# CY8C5868AXI_LP035 register map
File version: 0.1
CY8C58LP
Registers are 8-bit, read-write, no defined reset value unless marked. A register's access mark holds for its fields unless they carry their own. Offsets are from the block's base; lines under a group give offsets from that group; [hi:lo] are bit positions; {n}, {i} and the like mark numbered series; 'fields as' and 'values as' point back to an identical list; <NAME> marks a mode.

## Memory map
0x00000000 Rx_Top — UART
0x00000000 Rx_Bottom — UART
0x00000000 Rx_Front — UART
0x00000000 Rx_Left — UART
0x00000000 Rx_Right — UART
0x00000000 Tx — UART
0x00000000 Rx_Back — UART
0x40006460 Rx_Back_Register
0x40006462 Rx_Front_Register
0x40006566 Rx_Left_Register
0x40006567 Rx_Bottom_Register
0x40006568 Rx_Right_Register
0x4000656A Rx_Top_Register

## Rx_Top — UART
Base 0x00000000
0x40006429 RX_Rx_Top_RX_ADDRESS1 — RX Address1 Register
0x40006439 RX_Rx_Top_RX_ADDRESS2 — RX Address2 Register
0x40006449 RX_Rx_Top_RX_DATA — RX Data Register
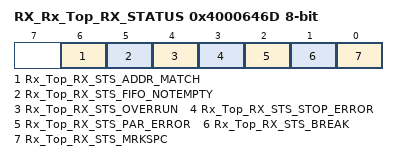
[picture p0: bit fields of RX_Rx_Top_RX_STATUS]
0x4000646D RX_Rx_Top_RX_STATUS — RX status register
  [6] Rx_Top_RX_STS_ADDR_MATCH ro, [5] Rx_Top_RX_STS_FIFO_NOTEMPTY ro, [4] Rx_Top_RX_STS_OVERRUN ro, [3] Rx_Top_RX_STS_STOP_ERROR ro, [2] Rx_Top_RX_STS_PAR_ERROR ro, [1] Rx_Top_RX_STS_BREAK ro, [0] Rx_Top_RX_STS_MRKSPC ro

## Rx_Back_Register
Base 0x40006460
0x00 Rx_Back_Register_STATUS_REG
0x20 Rx_Back_Register_MASK_REG
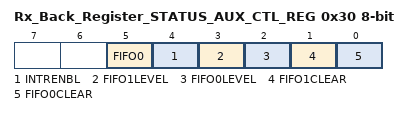
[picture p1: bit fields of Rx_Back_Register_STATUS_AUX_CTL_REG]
0x30 Rx_Back_Register_STATUS_AUX_CTL_REG
  [5] FIFO0 — FIFO0 clear
    1=ENABLED (Enable counter); 0=DISABLED (Disable counter)
  [4] INTRENBL — Enables or disables the Interrupt
    1=ENABLED (Interrupt enabled); 0=DISABLED (Interrupt disabled)
  [3] FIFO1LEVEL — FIFO level
    1=ENABLED (FIFO LVL: input mode: FIFO at least 1/2 empty; output mode: FIFO at least 1/2 full); 0=DISABLED (FIFO LVL: input mode: FIFO not full; output mode: FIFO not empty)
  [2] FIFO0LEVEL — FIFO level
    values as FIFO1LEVEL
  [1] FIFO1CLEAR — FIFO clear
    1=ENABLED (Clear FIFO state); 0=DISABLED (Normal FIFO operation)
  [0] FIFO0CLEAR — FIFO clear
    values as FIFO1CLEAR

## Rx_Left_Register
Base 0x40006566
Registers as Rx_Back_Register (with Rx_Back_Register read as Rx_Left_Register).

## Rx_Front_Register
Base 0x40006462
Registers as Rx_Back_Register (with Rx_Back_Register read as Rx_Front_Register).

## Rx_Bottom_Register
Base 0x40006567
Registers as Rx_Back_Register (with Rx_Back_Register read as Rx_Bottom_Register).

## Rx_Bottom — UART
Base 0x00000000
0x40006427 RX_Rx_Bottom_RX_ADDRESS1 — RX Address1 Register
0x40006437 RX_Rx_Bottom_RX_ADDRESS2 — RX Address2 Register
0x40006447 RX_Rx_Bottom_RX_DATA — RX Data Register
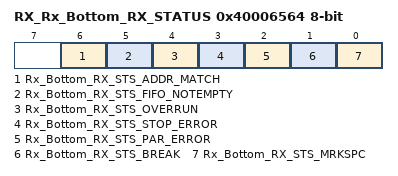
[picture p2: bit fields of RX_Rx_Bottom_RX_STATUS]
0x40006564 RX_Rx_Bottom_RX_STATUS — RX status register
  [6] Rx_Bottom_RX_STS_ADDR_MATCH ro, [5] Rx_Bottom_RX_STS_FIFO_NOTEMPTY ro, [4] Rx_Bottom_RX_STS_OVERRUN ro, [3] Rx_Bottom_RX_STS_STOP_ERROR ro, [2] Rx_Bottom_RX_STS_PAR_ERROR ro, [1] Rx_Bottom_RX_STS_BREAK ro, [0] Rx_Bottom_RX_STS_MRKSPC ro

## Rx_Right_Register
Base 0x40006568
Registers as Rx_Back_Register (with Rx_Back_Register read as Rx_Right_Register).

## Rx_Top_Register
Base 0x4000656A
Registers as Rx_Back_Register (with Rx_Back_Register read as Rx_Top_Register).

## Rx_Front — UART
Base 0x00000000
0x40006421 RX_Rx_Front_RX_ADDRESS1 — RX Address1 Register
0x40006431 RX_Rx_Front_RX_ADDRESS2 — RX Address2 Register
0x40006441 RX_Rx_Front_RX_DATA — RX Data Register
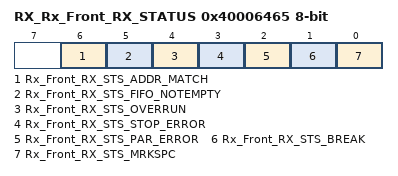
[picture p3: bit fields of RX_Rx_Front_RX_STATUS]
0x40006465 RX_Rx_Front_RX_STATUS — RX status register
  [6] Rx_Front_RX_STS_ADDR_MATCH ro, [5] Rx_Front_RX_STS_FIFO_NOTEMPTY ro, [4] Rx_Front_RX_STS_OVERRUN ro, [3] Rx_Front_RX_STS_STOP_ERROR ro, [2] Rx_Front_RX_STS_PAR_ERROR ro, [1] Rx_Front_RX_STS_BREAK ro, [0] Rx_Front_RX_STS_MRKSPC ro

## Rx_Left — UART
Base 0x00000000
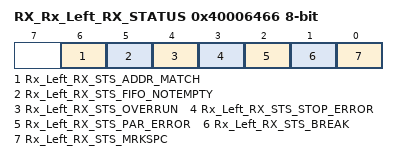
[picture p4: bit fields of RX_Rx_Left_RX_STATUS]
0x40006466 RX_Rx_Left_RX_STATUS — RX status register
  [6] Rx_Left_RX_STS_ADDR_MATCH ro, [5] Rx_Left_RX_STS_FIFO_NOTEMPTY ro, [4] Rx_Left_RX_STS_OVERRUN ro, [3] Rx_Left_RX_STS_STOP_ERROR ro, [2] Rx_Left_RX_STS_PAR_ERROR ro, [1] Rx_Left_RX_STS_BREAK ro, [0] Rx_Left_RX_STS_MRKSPC ro
0x40006525 RX_Rx_Left_RX_ADDRESS1 — RX Address1 Register
0x40006535 RX_Rx_Left_RX_ADDRESS2 — RX Address2 Register
0x40006545 RX_Rx_Left_RX_DATA — RX Data Register

## Rx_Right — UART
Base 0x00000000
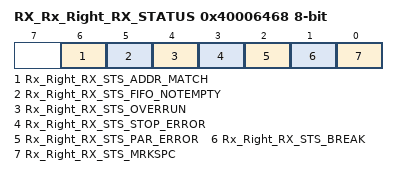
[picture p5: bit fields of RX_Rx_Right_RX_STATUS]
0x40006468 RX_Rx_Right_RX_STATUS — RX status register
  [6] Rx_Right_RX_STS_ADDR_MATCH ro, [5] Rx_Right_RX_STS_FIFO_NOTEMPTY ro, [4] Rx_Right_RX_STS_OVERRUN ro, [3] Rx_Right_RX_STS_STOP_ERROR ro, [2] Rx_Right_RX_STS_PAR_ERROR ro, [1] Rx_Right_RX_STS_BREAK ro, [0] Rx_Right_RX_STS_MRKSPC ro
0x4000652B RX_Rx_Right_RX_ADDRESS1 — RX Address1 Register
0x4000653B RX_Rx_Right_RX_ADDRESS2 — RX Address2 Register
0x4000654B RX_Rx_Right_RX_DATA — RX Data Register

## Tx — UART
Base 0x00000000
0x4000644C TX_Tx_TX_DATA — TX Data Register
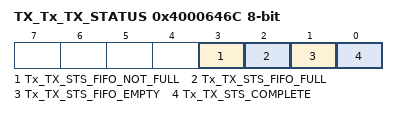
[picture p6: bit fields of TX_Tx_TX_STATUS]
0x4000646C TX_Tx_TX_STATUS — TX status register
  [3] Tx_TX_STS_FIFO_NOT_FULL ro, [2] Tx_TX_STS_FIFO_FULL ro, [1] Tx_TX_STS_FIFO_EMPTY ro, [0] Tx_TX_STS_COMPLETE ro

## Rx_Back — UART
Base 0x00000000
0x40006423 RX_Rx_Back_RX_ADDRESS1 — RX Address1 Register
0x40006433 RX_Rx_Back_RX_ADDRESS2 — RX Address2 Register
0x40006443 RX_Rx_Back_RX_DATA — RX Data Register
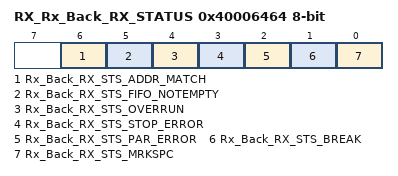
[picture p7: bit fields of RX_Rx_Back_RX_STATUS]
0x40006464 RX_Rx_Back_RX_STATUS — RX status register
  [6] Rx_Back_RX_STS_ADDR_MATCH ro, [5] Rx_Back_RX_STS_FIFO_NOTEMPTY ro, [4] Rx_Back_RX_STS_OVERRUN ro, [3] Rx_Back_RX_STS_STOP_ERROR ro, [2] Rx_Back_RX_STS_PAR_ERROR ro, [1] Rx_Back_RX_STS_BREAK ro, [0] Rx_Back_RX_STS_MRKSPC ro
